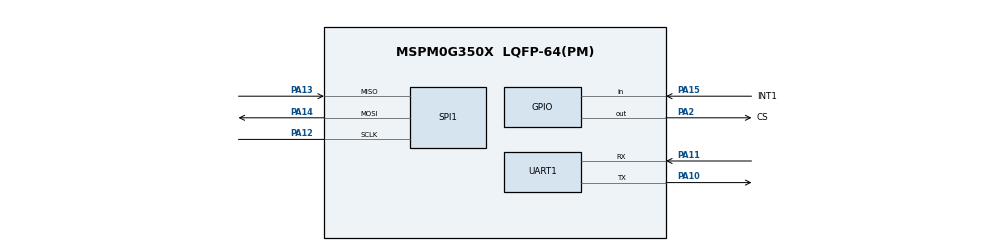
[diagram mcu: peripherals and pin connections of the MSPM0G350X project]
/**
 * @cliArgs --device "MSPM0G350X" --part "Default" --package "LQFP-64(PM)" --product "mspm0_sdk@2.04.00.06"
 * @versions {"tool":"1.23.1+4034"}
 */

/**
 * Import the modules used in this configuration.
 */
const Board         = scripting.addModule("/ti/driverlib/Board");
const GPIO          = scripting.addModule("/ti/driverlib/GPIO", {}, false);
const GPIO1         = GPIO.addInstance();
const SPI           = scripting.addModule("/ti/driverlib/SPI", {}, false);
const SPI1          = SPI.addInstance();
const SYSCTL        = scripting.addModule("/ti/driverlib/SYSCTL");
const UART          = scripting.addModule("/ti/driverlib/UART", {}, false);
const UART1         = UART.addInstance();
const ProjectConfig = scripting.addModule("/ti/project_config/ProjectConfig");

/**
 * Write custom configuration values to the imported modules.
 */
const divider6       = system.clockTree["PLL_CLK2X_DIV"];
divider6.divideValue = 4;

const divider7       = system.clockTree["PLL_PDIV"];
divider7.divideValue = 2;

const divider9       = system.clockTree["UDIV"];
divider9.divideValue = 2;

const multiplier2         = system.clockTree["PLL_QDIV"];
multiplier2.multiplyValue = 10;

const mux8       = system.clockTree["HSCLKMUX"];
mux8.inputSelect = "HSCLKMUX_SYSPLL2X";


GPIO1.port                           = "PORTA";
GPIO1.$name                          = "ICM42688";
GPIO1.associatedPins.create(2);
GPIO1.associatedPins[0].$name        = "INT1";
GPIO1.associatedPins[0].direction    = "INPUT";
GPIO1.associatedPins[0].interruptEn  = true;
GPIO1.associatedPins[0].polarity     = "RISE";
GPIO1.associatedPins[0].pin.$assign  = "PA15";
GPIO1.associatedPins[1].$name        = "CS";
GPIO1.associatedPins[1].initialValue = "SET";
GPIO1.associatedPins[1].pin.$assign  = "PA2";

SPI1.$name                      = "SPI_0";
SPI1.frameFormat                = "MOTO3";
SPI1.chipSelect                 = [];
SPI1.enableDMAEvent1            = false;
SPI1.enableDMAEvent2            = false;
SPI1.spiClkSrc                  = "BUSCLK";
SPI1.targetBitRate              = 16000000;
SPI1.sclkPinConfig.$name        = "ti_driverlib_gpio_GPIOPinGeneric2";
SPI1.mosiPinConfig.$name        = "ti_driverlib_gpio_GPIOPinGeneric3";
SPI1.misoPinConfig.$name        = "ti_driverlib_gpio_GPIOPinGeneric4";
SPI1.peripheral.$assign         = "SPI0";
SPI1.peripheral.sclkPin.$assign = "PA12";
SPI1.peripheral.mosiPin.$assign = "PA14";
SPI1.peripheral.misoPin.$assign = "PA13";

SYSCTL.MFCLKEn = true;

UART1.$name                    = "UART_0";
UART1.targetBaudRate           = 115200;
UART1.enableFIFO               = true;
UART1.rxFifoThreshold          = "DL_UART_RX_FIFO_LEVEL_ONE_ENTRY";
UART1.txFifoThreshold          = "DL_UART_TX_FIFO_LEVEL_ONE_ENTRY";
UART1.enableDMATX              = false;
UART1.enabledInterrupts        = ["RX"];
UART1.peripheral.$assign       = "UART0";
UART1.peripheral.rxPin.$assign = "PA11";
UART1.peripheral.txPin.$assign = "PA10";
UART1.txPinConfig.$name        = "ti_driverlib_gpio_GPIOPinGeneric7";
UART1.rxPinConfig.$name        = "ti_driverlib_gpio_GPIOPinGeneric8";

ProjectConfig.genDisable = true;
scripting.suppress("Project Configuration File generation is disabled for this project\\. SysConfig Project Migration is not currently supported for this project\\.", ProjectConfig);

/**
 * Pinmux solution for unlocked pins/peripherals. This ensures that minor changes to the automatic solver in a future
 * version of the tool will not impact the pinmux you originally saw.  These lines can be completely deleted in order to
 * re-solve from scratch.
 */
Board.peripheral.$suggestSolution          = "DEBUGSS";
Board.peripheral.swclkPin.$suggestSolution = "PA20";
Board.peripheral.swdioPin.$suggestSolution = "PA19";
SYSCTL.peripheral.$suggestSolution         = "SYSCTL";
